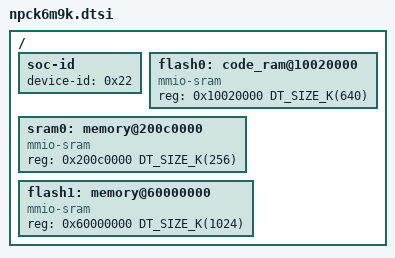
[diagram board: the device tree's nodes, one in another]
/*
 * Copyright (c) 2026 Nuvoton Technology Corporation.
 *
 * SPDX-License-Identifier: Apache-2.0
 */

#include <mem.h>
#include "npck/npck6.dtsi"

/ {
	soc-id {
		device-id = <0x22>;
	};

	/* Code ram */
	flash0: code_ram@10020000 {
		compatible = "mmio-sram";
		reg = <0x10020000 DT_SIZE_K(640)>;
		device_type = "memory";
	};

	/* Data ram */
	sram0: memory@200c0000 {
		compatible = "mmio-sram";
		reg = <0x200c0000 DT_SIZE_K(256)>;
		device_type = "memory";
	};

	flash1: memory@60000000 {
		compatible = "mmio-sram";
		reg = <0x60000000 DT_SIZE_K(1024)>;
		device_type = "memory";
	};
};
